# DSS_REG register map
Vendor: Texas Instruments
Peripheral module from a debugger description file (folder radar).
Registers are 32-bit, read-write, no defined reset value unless marked. A register's access mark holds for its fields unless they carry their own. Offsets are as the file gives them; lines under a group give offsets from that group; [hi:lo] are bit positions; {n}, {i} and the like mark numbered series; 'fields as' and 'values as' point back to an identical list; <NAME> marks a mode.

## DSS_REG
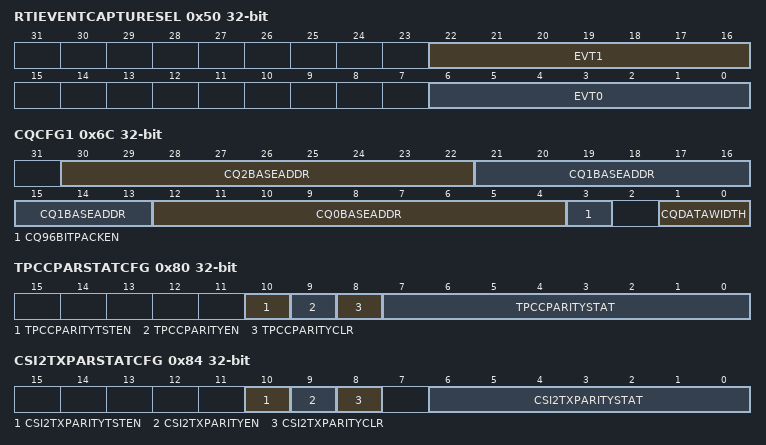
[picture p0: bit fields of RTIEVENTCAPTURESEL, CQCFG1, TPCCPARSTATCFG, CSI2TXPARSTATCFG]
0x50 RTIEVENTCAPTURESEL
  [22:16] EVT1 — Setting the source of interrupt for Counter value capture for RTI1 Event1
  [6:0] EVT0 — Setting the source of interrupt for Counter value capture for RTI1 Event0.
0x6C CQCFG1
  [30:22] CQ2BASEADDR — 128-bit Address offset which inidcates the start address for storing CQ0 (ADC/RxIF Saturation Detection) from the start of CQ memory. This is not the byte address offset but 128 bit address offset
  [21:13] CQ1BASEADDR — 128-bit Address offset which inidcates the start address for storing CQ0 (Signal Image Band Energy detection) from the start of CQ memory. This is not the byte address offset but 128 bit address offset
  [12:4] CQ0BASEADDR — 128-bit Address offset which inidcates the start address for storing CQ0 (Wide Band Energy detection) from the start of CQ memory. This is not the byte address offset but 128 bit address offset
  [3] CQ96BITPACKEN — This is used to pack the CQ data into only the LSB 96 bits of each row of the CQ memory. This can be used in 3 channel mode of LVDS where the ADC data and Chirp Params occupy only LSB 96 bits of each memory row.
  [1:0] CQDATAWIDTH — This is used to appropriately pack the valid CQ data bits in appropriate bits in the CQ memory. 00, 01->Raw 16, 10-->Raw 12, 11-->Raw14
0x80 TPCCPARSTATCFG access not given
  [10] TPCCPARITYTSTEN rw — Enable bit for the self test of the Parity logic in TPCC
  [9] TPCCPARITYEN rw — Enable bit for the Parity computation in TPCC
  [8] TPCCPARITYCLR — Clear bit for the Parity error from TPCC Write 0x1 to clear the status
  [7:0] TPCCPARITYSTAT ro — Parity address from TPCC
0x84 CSI2TXPARSTATCFG access not given
  [10] CSI2TXPARITYTSTEN rw — Enable bit for the self test of the Parity logic in CSI2 FIFO
  [9] CSI2TXPARITYEN rw — Enable bit for the Parity computation in CSI2 FIFO
  [8] CSI2TXPARITYCLR — Clear bit for the Parity error from CSI2 FIFO Write 0x1 to clear the status
  [6:0] CSI2TXPARITYSTAT ro — TI Internal feature as this is a FIFO, Parity address from CSI2
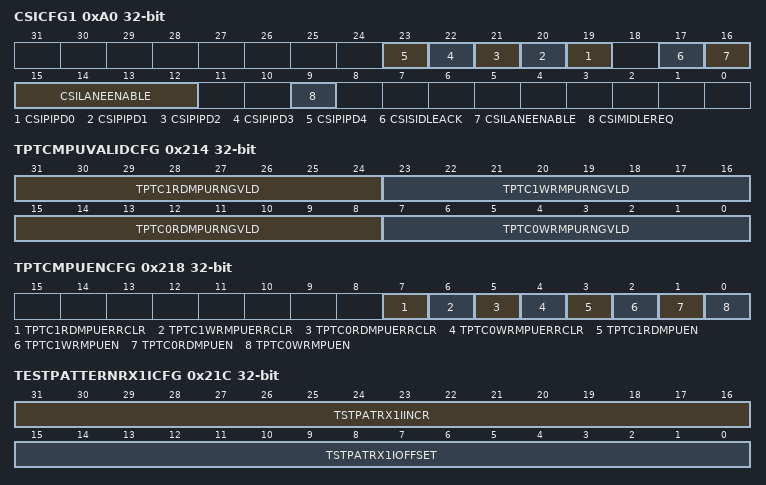
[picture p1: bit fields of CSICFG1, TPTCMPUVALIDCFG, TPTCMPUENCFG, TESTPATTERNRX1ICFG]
0xA0 CSICFG1 access per field
  [n+19] CSIPIPD{n} rw (n=0..4) — CSI2 Lane {n} PD Enable 0x0: Pull down enabled 0x1: Pull down disabled
  [17] CSISIDLEACK ro — Idle Status of CSI2 Protocol Engine 0 : CSI2 Protocol Engine is out of Idle 1 : CSI2 Protocol Engine is in Idle
  [16:12] CSILANEENABLE rw — CSI2 Lane Enable For each bit, the following settings are valid: 0x0: Lane module disabled 0x1: Lane module enabled [16] CSI2 lane 4 enable [15] CSI2 lane 3 enable [14] CSI2 lane 2 enable [13] CSI2 lane 1 enable [12] CSI2 lane 0 enable
  [9] CSIMIDLEREQ rw — Configuration to send an Idle request to the CSI2 IP 0 : Request the CSI2 Protocol Engine to come out of Idle 1 : Request the CSI2 Protocol Engine to go into idle mode
{0x104+4i} TPTC0WRMPUSTADD{i} (i=0..5)
  [31:0] TPTC0WRMPUSTADD{i} — Configure the Start address for Region {i} for the MPU on the write port of TPTC0
{0x124+4i} TPTC0WRMPUENDADD{i} (i=0..5)
  [31:0] TPTC0WRMPUENDADD{i} — Configure the End address for Region {i} for the MPU on the write port of TPTC0
0x144 TPTC0WRMPUERRADD ro
  [31:0] TPTC0WRMPUERRADD — Status register to Read the address that triggered an MPU error on the write port of TPTC0
{0x148+4i} TPTC0RDMPUSTADD{i} (i=0..5)
  [31:0] TPTC0RDMPUSTADD{i} — Configure the Start address for Region {i} for the MPU on the read port of TPTC0
{0x168+4i} TPTC0RDMPUENDADD{i} (i=0..5)
  [31:0] TPTC0RDMPUENDADD{i} — Configure the End address for Region {i} for the MPU on the read port of TPTC0
0x188 TPTC0RDMPUERRADD ro
  [31:0] TPTC0RDMPUERRADD — Status register to Read the address that triggered an MPU error on the read port of TPTC0
{0x18C+4i} TPTC1WRMPUSTADD{i} (i=0..5)
  [31:0] TPTC1WRMPUSTADD{i} — Configure the Start address for Region {i} for the MPU on the write port of TPTC1
{0x1AC+4i} TPTC1WRMPUENDADD{i} (i=0..5)
  [31:0] TPTC1WRMPUENDADD{i} — Configure the End address for Region {i} for the MPU on the write port of TPTC1
0x1CC TPTC1WRMPUERRADD ro
  [31:0] TPTC1WRMPUERRADD — Status register to Read the address that triggered an MPU error on the write port of TPTC1
{0x1D0+4i} TPTC1RDMPUSTADD{i} (i=0..5)
  [31:0] TPTC1RDMPUSTADD{i} — Configure the Start address for Region {i} for the MPU on the read port of TPTC1
{0x1F0+4i} TPTC1RDMPUENDADD{i} (i=0..5)
  [31:0] TPTC1RDMPUENDADD{i} — Configure the End address for Region {i} for the MPU on the read port of TPTC1
0x210 TPTC1RDMPUERRADD ro
  [31:0] TPTC1RDMPUERRADD — Status register to Read the address that triggered an MPU error on the read port of TPTC1
0x214 TPTCMPUVALIDCFG
  [31:24] TPTC1RDMPURNGVLD — Configure the Valid bit for each address range for the MPU in the read port of TPTC1. [0]->Address0 and [5]-->Address5 Each bit corresponds to a MPU region 0 : Region is disbaled 1 : Regsion is enabled
  [23:16] TPTC1WRMPURNGVLD — Configure the Valid bit for each address range for the MPU in the write port of TPTC1. [0]->Address0 and [5]-->Address5 Each bit corresponds to a MPU region 0 : Region is disbaled 1 : Regsion is enabled
  [15:8] TPTC0RDMPURNGVLD — Configure the Valid bit for each address range for the MPU in the read port of TPTC0. [0]->Address0 and [5]-->Address5 Each bit corresponds to a MPU region 0 : Region is disbaled 1 : Regsion is enabled
  [7:0] TPTC0WRMPURNGVLD — Configure the Valid bit for each address range for the MPU in the write port of TPTC0. [0]->Address0 and [5]-->Address5 Each bit corresponds to a MPU region 0 : Region is disbaled 1 : Regsion is enabled
0x218 TPTCMPUENCFG access not given
  [7] TPTC1RDMPUERRCLR — Clear flag for Error from the MPU in the read port of TPTC1. Write 0x1 to clear the MPU error
  [6] TPTC1WRMPUERRCLR — Clear flag for Error from the MPU in the write port of TPTC1. Write 0x1 to clear the MPU error
  [5] TPTC0RDMPUERRCLR — Clear flag for Error from the MPU in the read port of TPTC0. Write 0x1 to clear the MPU error
  [4] TPTC0WRMPUERRCLR — Clear flag for Error from the MPU in the write port of TPTC0. Write 0x1 to clear the MPU error
  [3] TPTC1RDMPUEN rw — Enable bit for the MPU in the read port of TPTC1. 0 : MPU is disabled 1 : MPU is enabled
  [2] TPTC1WRMPUEN rw — Enable bit for the MPU in the write port of TPTC1. 0 : MPU is disabled 1 : MPU is enabled
  [1] TPTC0RDMPUEN rw — Enable bit for the MPU in the read port of TPTC0. 0 : MPU is disabled 1 : MPU is enabled
  [0] TPTC0WRMPUEN rw — Enable bit for the MPU in the write port of TPTC0. 0 : MPU is disabled 1 : MPU is enabled
0x21C TESTPATTERNRX1ICFG
  [31:16] TSTPATRX1IINCR — Value to be added for each successive sample for the test pattern data in I channel Rx channel 0. In this register the naming convention for the 4 Rx channel indices are from 1 to 4 instead of 0 to 3.
  [15:0] TSTPATRX1IOFFSET — Offset value to be used for the first sample for the test pattern data in I channel Rx channel 0. In this register the naming convention for the 4 Rx channel indices are from 1 to 4 instead of 0 to 3.
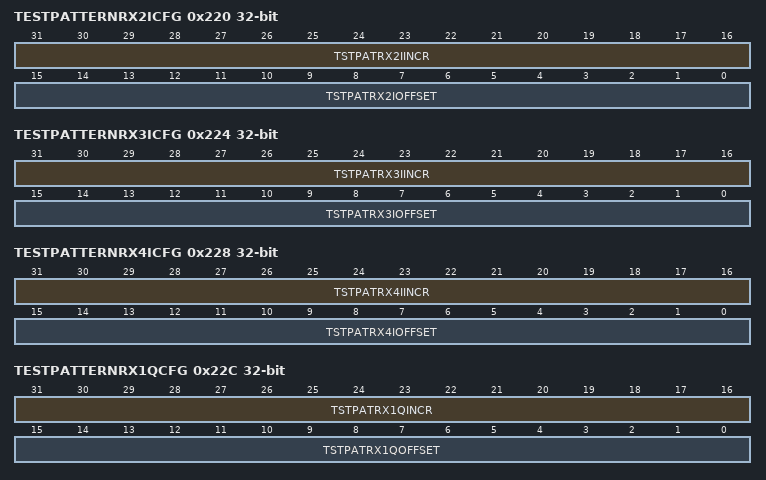
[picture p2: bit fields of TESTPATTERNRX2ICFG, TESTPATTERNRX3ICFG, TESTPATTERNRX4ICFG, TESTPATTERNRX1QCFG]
0x220 TESTPATTERNRX2ICFG
  [31:16] TSTPATRX2IINCR — Value to be added for each successive sample for the test pattern data in I channel Rx channel 1.
  [15:0] TSTPATRX2IOFFSET — Offset value to be used for the first sample for the test pattern data in I channel Rx channel 1.
0x224 TESTPATTERNRX3ICFG
  [31:16] TSTPATRX3IINCR — Value to be added for each successive sample for the test pattern data in I channel Rx channel 2
  [15:0] TSTPATRX3IOFFSET — Offset value to be used for the first sample for the test pattern data in I channel Rx channel 2
0x228 TESTPATTERNRX4ICFG
  [31:16] TSTPATRX4IINCR — Value to be added for each successive sample for the test pattern data in I channel Rx channel 3
  [15:0] TSTPATRX4IOFFSET — Offset value to be used for the first sample for the test pattern data in I channel Rx channel 3
0x22C TESTPATTERNRX1QCFG
  [31:16] TSTPATRX1QINCR — Value to be added for each successive sample for the test pattern data in Q channel Rx channel 0. In this register the naming convention for the 4 Rx channel indices are from 1 to 4 instead of 0 to 3.
  [15:0] TSTPATRX1QOFFSET — Offset value to be used for the first sample for the test pattern data in Q channel Rx channel 0. In this register the naming convention for the 4 Rx channel indices are from 1 to 4 instead of 0 to 3.
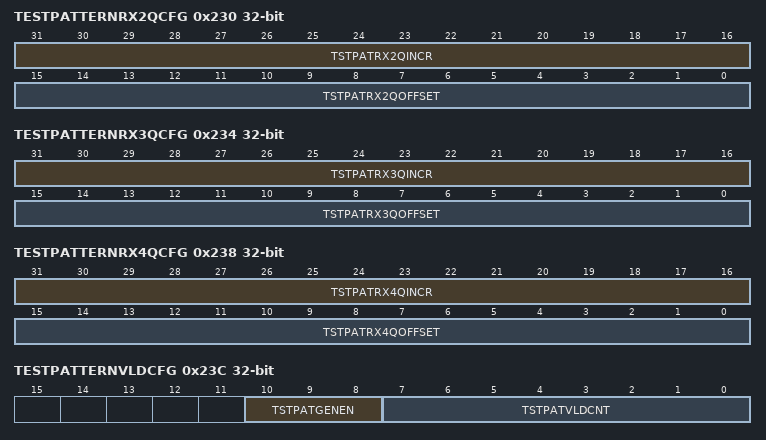
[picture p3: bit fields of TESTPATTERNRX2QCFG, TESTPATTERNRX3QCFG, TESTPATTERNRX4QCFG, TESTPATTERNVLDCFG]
0x230 TESTPATTERNRX2QCFG
  [31:16] TSTPATRX2QINCR — Value to be added for each successive sample for the test pattern data in Q channel Rx channel 1.
  [15:0] TSTPATRX2QOFFSET — Offset value to be used for the first sample for the test pattern data in Q channel Rx channel 1.
0x234 TESTPATTERNRX3QCFG
  [31:16] TSTPATRX3QINCR — Value to be added for each successive sample for the test pattern data in Q channel Rx channel 2
  [15:0] TSTPATRX3QOFFSET — Offset value to be used for the first sample for the test pattern data in Q channel Rx channel 2
0x238 TESTPATTERNRX4QCFG
  [31:16] TSTPATRX4QINCR — Value to be added for each successive sample for the test pattern data in Q channel Rx channel 3
  [15:0] TSTPATRX4QOFFSET — Offset value to be used for the first sample for the test pattern data in Q channel Rx channel 3
0x23C TESTPATTERNVLDCFG
  [10:8] TSTPATGENEN — Enable for test pattern generator. This is used to Mux with the functional data from BSS. 000 -->Disable, 111-->Enable, Others are reserved.
  [7:0] TSTPATVLDCNT — Number of DSS Interconnect clocks (200 MHz) between successive samples for the test pattern gen.
0x240 DSSMISC
  [8:6] FFTACCSLVEN — Enable HW Accelerator 000-->Disable, 111-->Enable, Others are reserved.
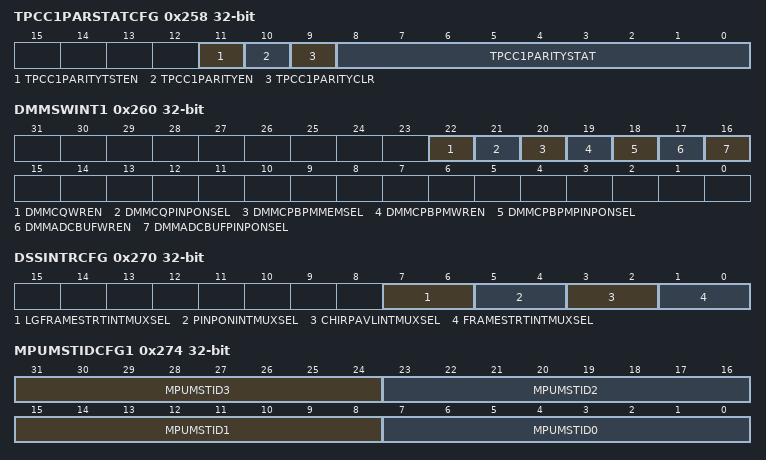
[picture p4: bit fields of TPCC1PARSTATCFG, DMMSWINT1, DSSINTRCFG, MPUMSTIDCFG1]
0x258 TPCC1PARSTATCFG access not given
  [11] TPCC1PARITYTSTEN rw — Enable bit for the self test of the Parity logic in TPCC
  [10] TPCC1PARITYEN rw — Enable bit for the Parity computation in TPCC
  [9] TPCC1PARITYCLR — Clear bit for the Parity error from TPCC Write 0x1 to clear the status
  [8:0] TPCC1PARITYSTAT ro — Parity address from TPCC
0x260 DMMSWINT1
  [22] DMMCQWREN — CQ Write Enable from DMM. 0 --> Write to CQ memory will happen from DFE and Ping-pong select will come from HW FSM (same as ADC Buffer ping-pong select). 1 --> Write to CQ memory will happen from CQ_W slave port in DSS interconnect using DMM as master and Ping-pong select will come from DMMCQPINPONSEL register.
  [21] DMMCQPINPONSEL — CQ Ping Pong select for HIL Mode
  [20] DMMCPBPMMEMSEL — Select signal for Muxing between HW Registers/Memory for CPBPM data. 0 --> Read access from CPBPM_MEM slave in DSS interconnect will be routed to HW Registers which is populated by DFE/RampGen, 1 --> Read access from CPBPM_MEM slave in DSS interconnect will be routed to appropriate CPBPM memory (Ping/Pong).
  [19] DMMCPBPMWREN — CPBPM Write Enable from DMM. 0 --> Ping-pong select will come from HW FSM (same as ADC Buffer ping-pong select). 1 --> Ping-pong select will come from DMMCPBPMPINPONSEL register.
  [18] DMMCPBPMPINPONSEL — CP BPM Ping Pong select for HIL Mode
  [17] DMMADCBUFWREN — ADC Buffer Write Enable from DMM. 0 --> Write to ADC BUF memory will happen from DFE and Ping-pong select will come from HW FSM (same as ADC Buffer ping-pong select). 1 --> Write to CQ memory will happen from ADCBUF_W slave port in DSS interconnect using DMM as master and Ping-pong select will come from DMMADCBUFPINPONSEL register.
  [16] DMMADCBUFPINPONSEL — ADC Buffer Ping Pong select for HIL Mode
0x270 DSSINTRCFG
  [7:6] LGFRAMESTRTINTMUXSEL — [0] - Used to select between DFE and DMM Global Logical Frame Start CFG Bit. 0 --> Select DFE Logical Frame Start, 1--> Select DMM Global Logical Frame start CFG Bit. [1] - Used to select between the result from above mentioned Mux and DMM SW Interrupt 0. 0 --> Selects the result of above mentioned mux. 1 --> Selects DMM SW Interrupt 3.
  [5:4] PINPONINTMUXSEL — [0] - Used to select between VIN/DFE and DMM Global Frame Start CFG Bit. 0 --> Select VIN/DFE Ping Pong Switch, 1--> Select DMM Global Ping Pong Switch CFG Bit. [1] - Used to select between the result from above mentioned Mux and DMM SW Interrupt 0. 0 --> Selects the result of above mentioned mux. 1 --> Selects DMM SW Interrupt 2.
  [3:2] CHIRPAVLINTMUXSEL — [0] - Used to select between VIN/DFE and DMM Global Frame Start CFG Bit. 0 --> Select VIN/DFE Chirp Available, 1--> Select DMM Global Chirp Available CFG Bit. [1] - Used to select between the result from above mentioned Mux and DMM SW Interrupt 0. 0 --> Selects the result of above mentioned mux. 1 --> Selects DMM SW Interrupt 1.
  [1:0] FRAMESTRTINTMUXSEL — [0] - Used to select between VIN/DFE and DMM Global Frame Start CFG Bit. 0 --> Select VIN/DFE Frame Start, 1--> Select DMM Global Frame start CFG Bit. [1] - Used to select between the result from above mentioned Mux and DMM SW Interrupt 0. 0 --> Selects the result of above mentioned mux. 1 --> Selects DMM SW Interrupt 0.
0x274 MPUMSTIDCFG1
  [31:24] MPUMSTID3 — MPU on the MSS -> DSS CFG. Only Masters with Master ID configured in MPUMSTID[0-7] are allowed to access the DSS CFG Space. Allowed MSTID3. Defaule value maps to RS232 Port
  [23:16] MPUMSTID2 — MPU on the MSS -> DSS CFG. Only Masters with Master ID configured in MPUMSTID[0-7] are allowed to access the DSS CFG Space. Allowed MSTID2. Defaule value maps to MSS DAP Port
  [15:8] MPUMSTID1 — MPU on the MSS -> DSS CFG. Only Masters with Master ID configured in MPUMSTID[0-7] are allowed to access the DSS CFG Space. Allowed MSTID0. Defaule value maps to MSS CR4 Read Port
  [7:0] MPUMSTID0 — MPU on the MSS -> DSS CFG. Only Masters with Master ID configured in MPUMSTID[0-7] are allowed to access the DSS CFG Space. Allowed MSTID0. Defaule value maps to MSS CR4 Read Port
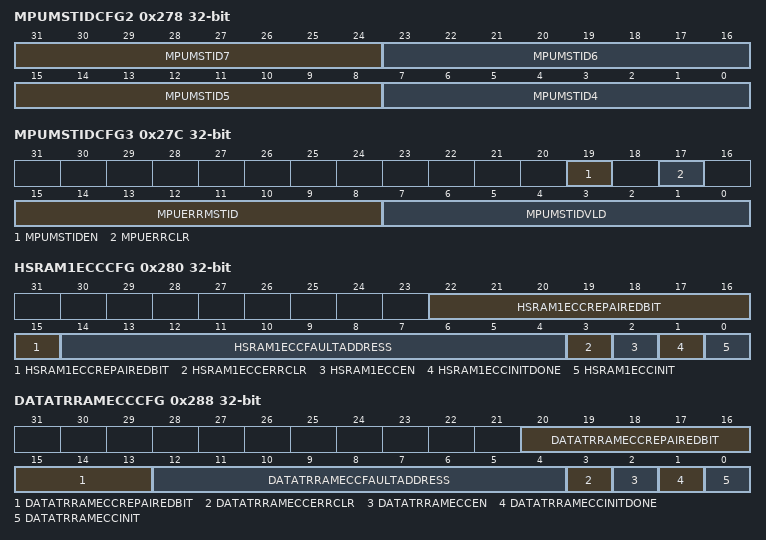
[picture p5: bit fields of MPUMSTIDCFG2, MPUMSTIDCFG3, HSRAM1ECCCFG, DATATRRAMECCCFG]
0x278 MPUMSTIDCFG2
  [31:24] MPUMSTID7 — MPU on the MSS -> DSS CFG. Only Masters with Master ID configured in MPUMSTID[0-7] are allowed to access the DSS CFG Space. Allowed MSTID7. Defaule value maps to RS232 Port
  [23:16] MPUMSTID6 — Allowed MSTID6. Defaule value maps to MSS DAP Port
  [15:8] MPUMSTID5 — MPU on the MSS -> DSS CFG. Only Masters with Master ID configured in MPUMSTID[0-7] are allowed to access the DSS CFG Space. Allowed MSTID5 Defaule value maps to MSS CR4 Write Port
  [7:0] MPUMSTID4 — MPU on the MSS -> DSS CFG. Only Masters with Master ID configured in MPUMSTID[0-7] are allowed to access the DSS CFG Space. Allowed MSTID4. Defaule value maps to MSS CR4 Read Port
0x27C MPUMSTIDCFG3 access not given
  [19] MPUMSTIDEN rw — Enable control for Master ID based MPU 0 --> Disabled, 1 --> Enabled
  [17] MPUERRCLR — Error clear pulse for Master ID based MPU Write 0x1 to clear the previous error status
  [15:8] MPUERRMSTID ro — Error status field. Provides the Master ID which is not part of the allowed list which caused an error.
  [7:0] MPUMSTIDVLD rw — Master ID valid. Each bit corresponds to the MPUMSTID[7:0] 0 : Master ID entry is valid 1 : Master ID entry is not valid and entry does not have access to DSS CFG Space
0x280 HSRAM1ECCCFG access not given
  [22:15] HSRAM1ECCREPAIREDBIT ro — Bit position of the repaired bit in HSRAM1
  [14:4] HSRAM1ECCFAULTADDRESS ro — ECC Fault address in HSRAM1
  [3] HSRAM1ECCERRCLR — Clear bit for ECC Error Indication in HSRAM1 Write 0x1 to clear the error status
  [2] HSRAM1ECCEN rw — Enable for ECC in HSRAM1
  [1] HSRAM1ECCINITDONE ro — Done status for ECC Init for HSRAM1
  [0] HSRAM1ECCINIT — ECC Init For HSRAM1
0x288 DATATRRAMECCCFG access not given
  [20:13] DATATRRAMECCREPAIREDBIT ro — Bit position of the repaired bit in DATATRRAM
  [12:4] DATATRRAMECCFAULTADDRESS ro — ECC Fault address in DATATRRAM
  [3] DATATRRAMECCERRCLR — Clear bit for ECC Error Indication in DATATRRAM Write 0x1 to clear the error status
  [2] DATATRRAMECCEN rw — Enable for ECC in DATATRRAM
  [1] DATATRRAMECCINITDONE ro — Done status for ECC Init for Data Transfer RAM
  [0] DATATRRAMECCINIT — ECC Init For Data Transfer RAM
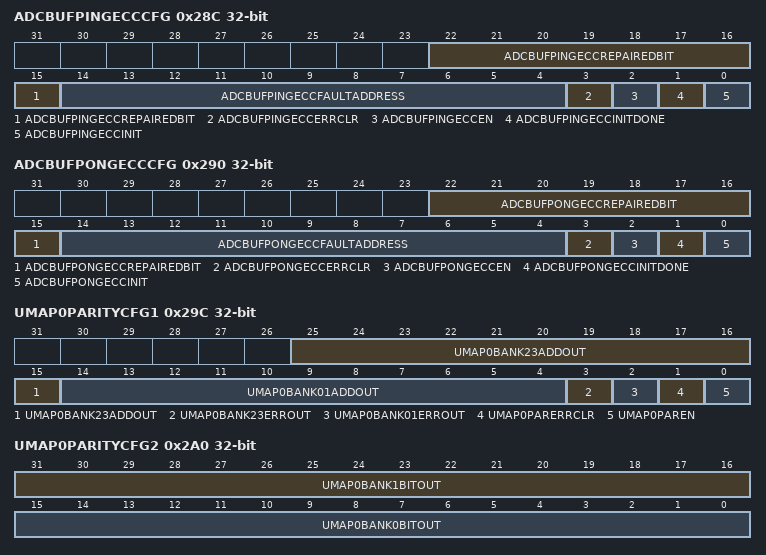
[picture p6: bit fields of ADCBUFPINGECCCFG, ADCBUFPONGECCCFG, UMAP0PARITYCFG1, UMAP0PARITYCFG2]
0x28C ADCBUFPINGECCCFG access not given
  [22:15] ADCBUFPINGECCREPAIREDBIT ro — Bit position of the repaired bit in ADC Buffer Ping Memory
  [14:4] ADCBUFPINGECCFAULTADDRESS ro — ECC Fault address in ADC Buffer Ping Memory
  [3] ADCBUFPINGECCERRCLR — Clear bit for ECC Error Indication in ADC Buffer Ping Memory Write 0x1 to clear the error status
  [2] ADCBUFPINGECCEN rw — Enable for ECC in ADC Buffer Ping Memory
  [1] ADCBUFPINGECCINITDONE ro — Done status for ECC Init for ADC Buffer Ping Memory
  [0] ADCBUFPINGECCINIT — ECC Init For ADC Buffer Ping Memory
0x290 ADCBUFPONGECCCFG access not given
  [22:15] ADCBUFPONGECCREPAIREDBIT ro — Bit position of the repaired bit in ADC Buffer Pong Memory
  [14:4] ADCBUFPONGECCFAULTADDRESS ro — ECC Fault address in ADC Buffer Pong Memory
  [3] ADCBUFPONGECCERRCLR — Clear bit for ECC Error Indication in ADC Buffer Pong Memory Write 0x1 to clear the error status
  [2] ADCBUFPONGECCEN rw — Enable for ECC in ADC Buffer Pong Memory
  [1] ADCBUFPONGECCINITDONE ro — Done status for ECC Init for ADC Buffer Pong Memory
  [0] ADCBUFPONGECCINIT — ECC Init For ADC Buffer Pong Memory
0x29C UMAP0PARITYCFG1 access not given
  [25:15] UMAP0BANK23ADDOUT ro — Address corresponding to the parity error in Bank2 or Bank3 of UMAP0.
  [14:4] UMAP0BANK01ADDOUT ro — Address corresponding to the parity error in Bank0 or Bank1 of UMAP0
  [3] UMAP0BANK23ERROUT ro — Parity Error indication from either Bank2 or Bank3 of UMAP0
  [2] UMAP0BANK01ERROUT ro — Parity Error indication from either Bank 0 or Bank1 of UMAP0
  [1] UMAP0PARERRCLR — Clear pulse for all the error status from UMAP0 parity check logic. Self-clearing pulse Write 0x1 to clear the error status
  [0] UMAP0PAREN rw — Enable for UMAP0 Parity Check logic. Assumed to be static. 0 --> Disable 1 --> Enable
0x2A0 UMAP0PARITYCFG2 ro
  [31:16] UMAP0BANK1BITOUT — Bit level indication corresponding to parity error from UMAP0 Bank1.
  [15:0] UMAP0BANK0BITOUT — Bit level indication corresponding to parity error from UMAP0 Bank0.
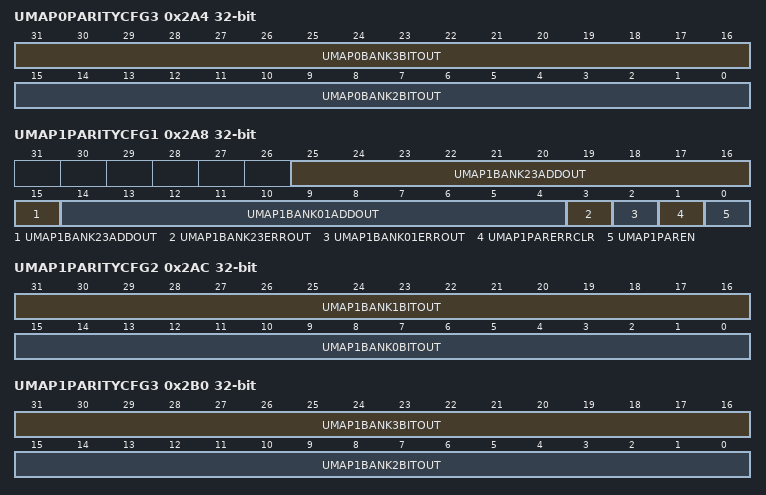
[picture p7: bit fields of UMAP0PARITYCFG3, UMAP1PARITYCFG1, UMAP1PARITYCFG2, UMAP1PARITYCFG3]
0x2A4 UMAP0PARITYCFG3 ro
  [31:16] UMAP0BANK3BITOUT — Bit level indication corresponding to parity error from UMAP0 Bank3.
  [15:0] UMAP0BANK2BITOUT — Bit level indication corresponding to parity error from UMAP0 Bank2.
0x2A8 UMAP1PARITYCFG1 access not given
  [25:15] UMAP1BANK23ADDOUT ro — Address corresponding to the parity error in Bank2 or Bank3 of UMAP1.
  [14:4] UMAP1BANK01ADDOUT ro — Address corresponding to the parity error in Bank0 or Bank1 of UMAP1
  [3] UMAP1BANK23ERROUT ro — Parity Error indication from either Bank2 or Bank3 of UMAP1
  [2] UMAP1BANK01ERROUT ro — Parity Error indication from either Bank 0 or Bank1 of UMAP1
  [1] UMAP1PARERRCLR — Clear pulse for all the error status from UMAP1 parity check logic. Self-clearing pulse Write 0x1 to clear the error status
  [0] UMAP1PAREN rw — Enable for UMAP1 Parity Check logic. Assumed to be static. 0 --> Disable 1 --> Enable
0x2AC UMAP1PARITYCFG2 ro
  [31:16] UMAP1BANK1BITOUT — Bit level indication corresponding to parity error from UMAP1 Bank1.
  [15:0] UMAP1BANK0BITOUT — Bit level indication corresponding to parity error from UMAP1 Bank0.
0x2B0 UMAP1PARITYCFG3 ro
  [31:16] UMAP1BANK3BITOUT — Bit level indication corresponding to parity error from UMAP1 Bank3.
  [15:0] UMAP1BANK2BITOUT — Bit level indication corresponding to parity error from UMAP1 Bank2.
0x2B4 ESMGRP2MASKCFG
  [31:0] ESMGRP2MASK — Bbit level mask for each of the error signal connected to ESM Group2 input.
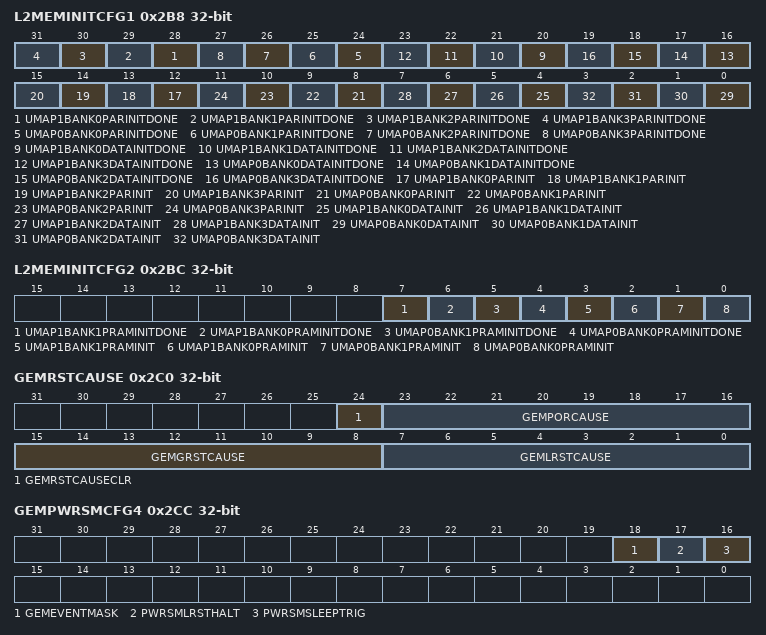
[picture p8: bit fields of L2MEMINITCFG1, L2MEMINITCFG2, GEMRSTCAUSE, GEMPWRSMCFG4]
0x2B8 L2MEMINITCFG1 access not given
  [n+28] UMAP1BANK{n}PARINITDONE ro (n=0..3) — Init Done status from UMAP1 Bank{n} Parity memory
  [n+24] UMAP0BANK{n}PARINITDONE ro (n=0..3) — Init Done status from UMAP0 Bank{n} Parity memory
  [n+20] UMAP1BANK{n}DATAINITDONE ro (n=0..3) — Init Done status from UMAP1 Bank{n} Data memory
  [n+16] UMAP0BANK{n}DATAINITDONE ro (n=0..3) — Init Done status from UMAP0 Bank{n} Data memory
  [n+12] UMAP1BANK{n}PARINIT (n=0..3) — Init trigger for UMAP1 Bank{n} Parity memory
  [n+8] UMAP0BANK{n}PARINIT (n=0..3) — Init trigger for UMAP0 Bank{n} Parity memory
  [n+4] UMAP1BANK{n}DATAINIT (n=0..3) — Init trigger for UMAP1 Bank{n} Data memory
  [n] UMAP0BANK{n}DATAINIT (n=0..3) — Init trigger for UMAP0 Bank{n} Data memory
0x2BC L2MEMINITCFG2 access not given
  [7] UMAP1BANK1PRAMINITDONE ro — Init Done Status for UMAP1 Bank1 PRAM memory
  [6] UMAP1BANK0PRAMINITDONE ro — Init Done Status for UMAP1 Bank0 PRAM memory
  [5] UMAP0BANK1PRAMINITDONE ro — Init Done Status for UMAP0 Bank1 PRAM memory
  [4] UMAP0BANK0PRAMINITDONE ro — Init Done Status for UMAP0 Bank0 PRAM memory
  [3] UMAP1BANK1PRAMINIT — Init trigger for UMAP1 Bank1 PRAM memory
  [2] UMAP1BANK0PRAMINIT — Init trigger for UMAP1 Bank0 PRAM memory
  [1] UMAP0BANK1PRAMINIT — Init trigger for UMAP0 Bank1 PRAM memory
  [0] UMAP0BANK0PRAMINIT — Init trigger for UMAP0 Bank0 PRAM memory
0x2C0 GEMRSTCAUSE access not given
  [24] GEMRSTCAUSECLR — Write 0x1 to clear the reset cause register for any previous resets
  [23:16] GEMPORCAUSE ro — TRM Description : Only show the resets that are exposed in TOPRCM TI Restricted Description DSP POR reset Bitwise Indication : Bit 0 : Por Reset Bit 1 : Sub system Reset from TOPRCM Bit 2 : Reset from TOPRCM Bit 3 : Reset from Power FSM Bit 4 : Reset from STC FSM
  [15:8] GEMGRSTCAUSE ro — TRM Description : Only show the resets that are exposed in TOPRCM TI Restricted Description DSP Greset Bitwise Indication : Bit 0 : Por Reset Bit 1 : Sub system Reset from TOPRCM Bit 2 : Rese from TOPRCM Bit 3 : Reset from Power FSM Bit 4 : Reset from STC FSM
  [7:0] GEMLRSTCAUSE ro — TRM Description : Only show the resets that are exposed in TOPRCM TI Restricted Description DSP Lreset Bitwise Indication : Bit 0 : Por Reset Bit 1 : Sub system Reset from TOPRCM Bit 2 : Reset from TOPRCM Bit 3 : Reset from Debugss Bit 4 : Reset from Power FSM Bit 5 : Reset from STC FSM
0x2C8 GEMPWRSMCFG3 ro
  [19:18] PWRSMMODESTATUS — Power Mode status of GEM. 00 --> Powered OFF, 01 --> Transitioning from OFF to ON state. 10 --> Transitioning from ON to OFF state. 11 --> Powered ON.
0x2CC GEMPWRSMCFG4 access not given
  [18] GEMEVENTMASK rw — Mask bit for events going to DSP. When this bit is set (during GEM sleep/power down mode), the events are monitored outside and will be available for DSP to read and clear them once GEM wakes-up. The monitored events can be read from PWRSMEVNTMONSTATx registers.
  [17] PWRSMLRSTHALT rw — Signal to halt DSP Power cycle state machine before de-asserting LRST of DSP. This is used during code download for the first time power up.
  [16] PWRSMSLEEPTRIG — Sleep mode trigger for DSP power down state machine. This will be honoured only when DSP is in GEM_ON state.
{0x2D4+4i} PWRSMWAKEMASK{i} (i=0..2)
  [31:0] PWRSMWAKEMASK{i} — Bit level mask for each of the wakeup source bits [{32i+31}:{32i}] 1 --> Masked, 0 --> Unmasked.
{0x2E0+4i} PWRSMMISEVTMASK{i} (i=0..2)
  [31:0] PWRSMMISEVTMASK{i} — Bit level mask for each of the missed events before getting pushed into GEM. Corresponds to Event lines[{32i+31}:{32i}] 1 --> Masked, 0 --> Unmasked.
0x2EC PWRSMWAKESRCSTAT0 ro
  [31:0] PWRSMWAKESRCSTAT0 — Wakeup source status bits [31:0]
0x2F0 PWRSMWAKESRCSTAT1 ro
  [31:0] PWRSMWAKESRCSTAT1 — Wakeup source status bits [63:32]
0x320 PWRSMWAKESRCSTAT2 ro
  [31:0] PWRSMWAKESRCSTAT2 — Wakeup source status bits [95:64]
0x324 PWRSMEVNTMONSTAT0 ro
  [31:0] PWRSMEVNTMONSTAT0 — Missed events monitor status bits [31:0]. This is monitored when the events going to DSP are masked by GEMEVENTMASK register.
0x328 PWRSMEVNTMONSTAT1 ro
  [31:0] PWRSMEVNTMONSTAT1 — Missed events monitor status bits [63:32]
0x32C PWRSMEVNTMONSTAT2 ro
  [31:0] PWRSMEVNTMONSTAT2 — Missed events monitor status bits [95:64]
{0x330+4i} PWRSMWAKESRCSTATCLR{i} access not given (i=0..2)
  [31:0] PWRSMWAKESRCSTATCLR{i} — Clear bit for wakeup source status bits [{32i+31}:{32i}]. Write 0x1 to clear the corrsponding status bit
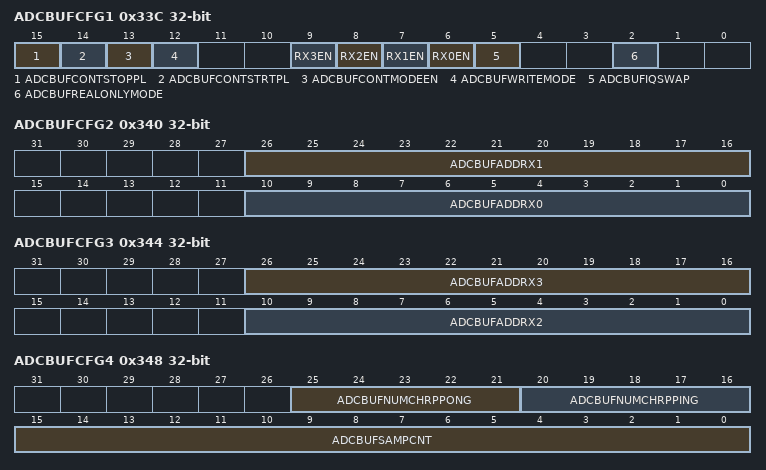
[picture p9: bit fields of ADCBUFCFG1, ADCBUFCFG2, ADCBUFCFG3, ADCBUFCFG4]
0x33C ADCBUFCFG1 access not given
  [15] ADCBUFCONTSTOPPL — Stop Pulse for Continuous mode. The data capture will stop once this register is set. Continous mode is expected to be only used for CZ and ADC Buffer Testpattern mode
  [14] ADCBUFCONTSTRTPL — Start Pulse for Continuous mode. The data capture will start from Address 0 once this register is set. All the other configurations like Enable, Sample Count are expected to be programmed before this pulse. Continous mode is expected to be only used for CZ and ADC Buffer Testpattern mode
  [13] ADCBUFCONTMODEEN rw — Continuous mode enable for ADC Buffer. This is set when a fixed number of samples have to be stored in Ping/Pong and not depend on Chirp time-lines (Eg: Analog Lab characterization to stream out continuous data from DFE). Continous mode is expected to be only used for CZ and ADC Buffer Testpattern mode
  [12] ADCBUFWRITEMODE rw — This needs to be programmed to 0x1 in AR16xx 0 --> Interleaved, 1 --> Non-interleaved
  [n+6] RX{n}EN rw (n=0..3) — Enable for Rx{n} write
  [5] ADCBUFIQSWAP rw — 0 --> I is stored in LSB and Q is stored in MSB 1 --> Q is stored in LSB and I is stored in MSB
  [2] ADCBUFREALONLYMODE rw — 0-->Complex Data mode, 1-->Real data mode
0x340 ADCBUFCFG2
  [26:16] ADCBUFADDRX1 — 128 bit Address offset to be added to the internal address pointer for Rx1 writes in Non-interleaved mode.
  [10:0] ADCBUFADDRX0 — 128 bit Address offset to be added to the internal address pointer for Rx0 writes in Non-interleaved mode.
0x344 ADCBUFCFG3
  [26:16] ADCBUFADDRX3 — 128 bit Address offset to be added to the internal address pointer for Rx3 writes in Non-interleaved mode.
  [10:0] ADCBUFADDRX2 — 128 bit Address offset to be added to the internal address pointer for Rx2 writes in Non-interleaved mode.
0x348 ADCBUFCFG4
  [25:21] ADCBUFNUMCHRPPONG — Number of chirps to be stored in Pong buffer. This register should be programmed with one less than the actual number needed. This is used when data is written to Pong Memory. The value written to this field should be the same as that configured for Ping
  [20:16] ADCBUFNUMCHRPPING — Number of chirps to be stored in Ping buffer. This register should be programmed with one less than the actual number needed. This is used when data is written to Pong Memory. The value written to this field should be the same as that configured for Pong
  [15:0] ADCBUFSAMPCNT — No of samples to store in each Ping and Pong register in continuous mode of ADC Buffer. In real only mode this refers to the number of real samples and in complex mode, this refers to number of complex samples. This refers to the number of samples per channel. This counter increments once for every new sample from DFE (as long as 1 or more channels are enabled). The max allowed value varies depending on other configurations (No of channels enabled and real/complex data). Continous mode is expected to be only used for CZ and ADC Buffer Testpattern mode
0x34C STCPBISTSMCFG1
  [3] STCPBISTLRSTDASRTHALT — Configuration to halt the state machine before the final de-assertion of LRST to enable program download. 1 --> Halt, 0 --> Proceed.
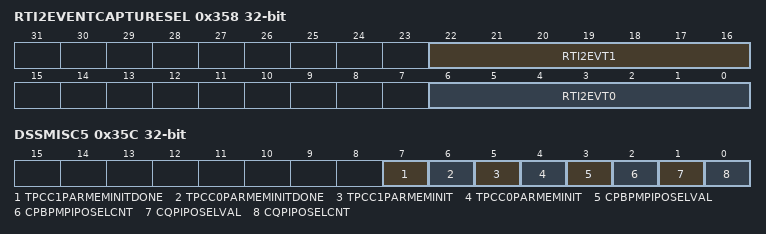
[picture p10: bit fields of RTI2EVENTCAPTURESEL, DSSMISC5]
0x358 RTI2EVENTCAPTURESEL
  [22:16] RTI2EVT1 — Used to Select the event to be captured for RTI2 Event1.
  [6:0] RTI2EVT0 — Used to Select the event to be captured for RTI2 Event0.
0x35C DSSMISC5 access not given
  [7] TPCC1PARMEMINITDONE ro — Mem init done status for the TPCC1 parity memory
  [6] TPCC0PARMEMINITDONE ro — Mem init done status for the TPCC0 parity memory
  [5] TPCC1PARMEMINIT — Mem init for the TPCC1 parity memory
  [4] TPCC0PARMEMINIT — Mem init for the TPCC0 parity memory
  [3] CPBPMPIPOSELVAL rw — Ping pong select override value for CPBPM Memory. 1 --> Read access from CPBPM_MEM Slave of DSS Interconnect will be routed to ping memory and write access from CPBPM_W write will be routed to pong memory. 0 --> Read access from CPBPM_MEM Slave of DSS Interconnect will be routed to pong memory and write access from CPBPM_W write will be routed to ping memory.
  [2] CPBPMPIPOSELCNT rw — Ping pong select override control for CPBPM Memory. 0 --> Ping-pong select comes from HW FSM (same as the ping-pong select for ADC Buffer)/DMMCPBPMPINPONSEL 1 --> Ping pong select for CPBPM memory is taken from SW register (CPBPMPIPOSELVAL)
  [1] CQPIPOSELVAL rw — Ping pong select override value for CQ Memory. 1 --> Read access from Chirp Info Slave of DSS Interconnect will be routed to ping memory and write access from CQ_W/DFE write will be routed to pong memory. 0 --> Read access from Chirp Info Slave of DSS Interconnect will be routed to pong memory and write access from CQ_W/DFE write will be routed to ping memory.
  [0] CQPIPOSELCNT rw — Ping pong select override control for CQ Memory. 0 --> Ping-pong select comes from HW FSM (same as the ping-pong select for ADC Buffer)/DMMCQPINPONSEL 1 --> Ping pong select for CQ memory is taken from SW register (CQPIPOSELVAL)
